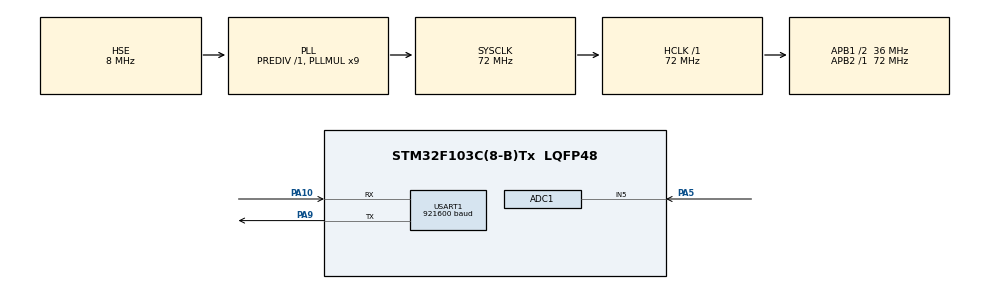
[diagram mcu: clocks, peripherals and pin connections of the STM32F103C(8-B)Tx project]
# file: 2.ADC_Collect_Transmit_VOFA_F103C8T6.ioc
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ADC1.Channel-0\#ChannelRegularConversion=ADC_CHANNEL_5
ADC1.ContinuousConvMode=DISABLE
ADC1.ExternalTrigConv=ADC_EXTERNALTRIGCONV_T3_TRGO
ADC1.NbrOfConversion=1
ADC1.NbrOfConversionFlag=1
ADC1.Rank-0\#ChannelRegularConversion=1
ADC1.SamplingTime-0\#ChannelRegularConversion=ADC_SAMPLETIME_55CYCLES_5
ADC1.master=1
Dma.ADC1.0.Direction=DMA_PERIPH_TO_MEMORY
Dma.ADC1.0.Instance=DMA1_Channel1
Dma.ADC1.0.MemDataAlignment=DMA_MDATAALIGN_HALFWORD
Dma.ADC1.0.MemInc=DMA_MINC_ENABLE
Dma.ADC1.0.Mode=DMA_CIRCULAR
Dma.ADC1.0.PeriphDataAlignment=DMA_PDATAALIGN_HALFWORD
Dma.ADC1.0.PeriphInc=DMA_PINC_DISABLE
Dma.ADC1.0.Priority=DMA_PRIORITY_MEDIUM
Dma.Request0=ADC1
Mcu.Family=STM32F1
Mcu.Name=STM32F103C(8-B)Tx
Mcu.Package=LQFP48
NVIC.DMA1_Channel1_IRQn=true\:0\:0\:false\:false\:true\:false\:true\:true
NVIC.PriorityGroup=NVIC_PRIORITYGROUP_4
PA10.Mode=Asynchronous
PA10.Signal=USART1_RX
PA13.Mode=Serial_Wire
PA13.Signal=SYS_JTMS-SWDIO
PA14.Mode=Serial_Wire
PA14.Signal=SYS_JTCK-SWCLK
PA5.Signal=ADCx_IN5
PA9.Mode=Asynchronous
PA9.Signal=USART1_TX
PD0-OSC_IN.Mode=HSE-External-Oscillator
PD0-OSC_IN.Signal=RCC_OSC_IN
PD1-OSC_OUT.Mode=HSE-External-Oscillator
PD1-OSC_OUT.Signal=RCC_OSC_OUT
ProjectManager.HeapSize=0x200
ProjectManager.StackSize=0x400
ProjectManager.TargetToolchain=CMake
RCC.ADCPresc=RCC_ADCPCLK2_DIV6
RCC.AHBFreq_Value=72000000
RCC.APB1CLKDivider=RCC_HCLK_DIV2
RCC.APB1Freq_Value=36000000
RCC.APB1TimFreq_Value=72000000
RCC.APB2Freq_Value=72000000
RCC.APB2TimFreq_Value=72000000
RCC.HCLKFreq_Value=72000000
RCC.PLLMUL=RCC_PLL_MUL9
RCC.PLLSourceVirtual=RCC_PLLSOURCE_HSE
RCC.SYSCLKFreq_VALUE=72000000
RCC.SYSCLKSource=RCC_SYSCLKSOURCE_PLLCLK
RCC.USBFreq_Value=72000000
SH.ADCx_IN5.0=ADC1_IN5,IN5
TIM3.Period=89
TIM3.Prescaler=79
TIM3.TIM_MasterOutputTrigger=TIM_TRGO_UPDATE
USART1.BaudRate=921600
USART1.VirtualMode=VM_ASYNC
VP_TIM3_VS_ClockSourceINT.Mode=Internal
board=custom

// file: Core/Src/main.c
/* USER CODE BEGIN Header */
/**
  ******************************************************************************
  * @file           : main.c
  * @brief          : Main program body
  ******************************************************************************
  * @attention
  *
  * Copyright (c) 2026 STMicroelectronics.
  * All rights reserved.
  *
  * This software is licensed under terms that can be found in the LICENSE file
  * in the root directory of this software component.
  * If no LICENSE file comes with this software, it is provided AS-IS.
  *
  ******************************************************************************
  */
/* USER CODE END Header */
#include "main.h"
#include "adc.h"
#include "dma.h"
#include "tim.h"
#include "usart.h"
#include "gpio.h"

/* USER CODE BEGIN PV */
extern TIM_HandleTypeDef htim3;             // CubeMX 自动生成在 main.c 全局区
extern uint16_t adc_dma_buf[200];           // 引用 adc.c 的 DMA 缓冲
#define ADC_BUF_SIZE  200
#define HALF_BUF      100

volatile uint8_t half_done = 0;             // 前半满标志
volatile uint8_t full_done = 0;             // 全满标志

float volt_filtered[HALF_BUF];              // 滤波后的浮点电压（供发送）
/* USER CODE END PV */

void SystemClock_Config(void);

/* USER CODE BEGIN 0 */
/* 4 点滑动平均滤波 */
static float smooth_filter(uint16_t *buf, int idx)
{
    int i0 = (idx - 3 + ADC_BUF_SIZE) % ADC_BUF_SIZE;
    int i1 = (idx - 2 + ADC_BUF_SIZE) % ADC_BUF_SIZE;
    int i2 = (idx - 1 + ADC_BUF_SIZE) % ADC_BUF_SIZE;
    float sum = buf[i0] + buf[i1] + buf[i2] + buf[idx];
    return sum * (3.3f / 4095.0f / 4.0f);  // 平均值转为电压
}

/* DMA 前半传输完成回调 */
void HAL_ADC_ConvHalfCpltCallback(ADC_HandleTypeDef* hadc)
{
    if (hadc->Instance == ADC1) {
        for (int i = 0; i < HALF_BUF; i++) {
            volt_filtered[i] = smooth_filter(adc_dma_buf, i);
        }
        half_done = 1;
    }
}

/* DMA 全满传输完成回调 */
void HAL_ADC_ConvCpltCallback(ADC_HandleTypeDef* hadc)
{
    if (hadc->Instance == ADC1) {
        for (int i = HALF_BUF; i < ADC_BUF_SIZE; i++) {
            volt_filtered[i - HALF_BUF] = smooth_filter(adc_dma_buf, i);
        }
        full_done = 1;
    }
}
/* USER CODE END 0 */

int main(void)
{

  /* MCU Configuration--------------------------------------------------------*/

  /* Reset of all peripherals, Initializes the Flash interface and the Systick. */
  HAL_Init();

  /* Configure the system clock */
  SystemClock_Config();

  /* Initialize all configured peripherals */
  MX_GPIO_Init();
  MX_DMA_Init();
  MX_ADC1_Init();
  MX_USART1_UART_Init();
  MX_TIM3_Init();
  /* USER CODE BEGIN 2 */
  /* 手动初始化 PB8 为推挽输出（调试 LED，低电平点亮）*/
  /* LED 初始化 */
  __HAL_RCC_GPIOB_CLK_ENABLE();
  GPIO_InitTypeDef GPIO_InitStruct = {0};
  GPIO_InitStruct.Pin = GPIO_PIN_8;
  GPIO_InitStruct.Mode = GPIO_MODE_OUTPUT_PP;
  GPIO_InitStruct.Pull = GPIO_NOPULL;
  GPIO_InitStruct.Speed = GPIO_SPEED_FREQ_LOW;
  HAL_GPIO_Init(GPIOB, &GPIO_InitStruct);
  /* 启动 TIM3，它将以 10kHz 触发 ADC */
  HAL_TIM_Base_Start(&htim3);

  /* USER CODE END 2 */

  /* Infinite loop */
  while (1)
  {

    /* USER CODE BEGIN 3 */
   /* 处理前半缓冲 */
    if (half_done) {
        half_done = 0;
        for (int i = 0; i < HALF_BUF; i++) {
            HAL_UART_Transmit(&huart1, (uint8_t*)&volt_filtered[i], 4, 10);
            uint8_t tail_magic[4] = {0x00, 0x00, 0x80, 0x7F};
            HAL_UART_Transmit(&huart1, tail_magic, 4, 10);
        }
        HAL_GPIO_TogglePin(GPIOB, GPIO_PIN_8);  // LED 翻转 = 数据已发送
    }

    /* 处理后半缓冲 */
    if (full_done) {
        full_done = 0;
        for (int i = 0; i < HALF_BUF; i++) {
            HAL_UART_Transmit(&huart1, (uint8_t*)&volt_filtered[i], 4, 10);
            uint8_t tail_magic[4] = {0x00, 0x00, 0x80, 0x7F};
            HAL_UART_Transmit(&huart1, tail_magic, 4, 10);
        }
        HAL_GPIO_TogglePin(GPIOB, GPIO_PIN_8);
    }
  }
  /* USER CODE END 3 */
}

void SystemClock_Config(void)
{
  RCC_OscInitTypeDef RCC_OscInitStruct = {0};
  RCC_ClkInitTypeDef RCC_ClkInitStruct = {0};
  RCC_PeriphCLKInitTypeDef PeriphClkInit = {0};

  /** Initializes the RCC Oscillators according to the specified parameters
  * in the RCC_OscInitTypeDef structure.
  */
  RCC_OscInitStruct.OscillatorType = RCC_OSCILLATORTYPE_HSE;
  RCC_OscInitStruct.HSEState = RCC_HSE_ON;
  RCC_OscInitStruct.HSEPredivValue = RCC_HSE_PREDIV_DIV1;
  RCC_OscInitStruct.HSIState = RCC_HSI_ON;
  RCC_OscInitStruct.PLL.PLLState = RCC_PLL_ON;
  RCC_OscInitStruct.PLL.PLLSource = RCC_PLLSOURCE_HSE;
  RCC_OscInitStruct.PLL.PLLMUL = RCC_PLL_MUL9;
  if (HAL_RCC_OscConfig(&RCC_OscInitStruct) != HAL_OK)
  {
    Error_Handler();
  }

  /** Initializes the CPU, AHB and APB buses clocks
  */
  RCC_ClkInitStruct.ClockType = RCC_CLOCKTYPE_HCLK|RCC_CLOCKTYPE_SYSCLK
                              |RCC_CLOCKTYPE_PCLK1|RCC_CLOCKTYPE_PCLK2;
  RCC_ClkInitStruct.SYSCLKSource = RCC_SYSCLKSOURCE_PLLCLK;
  RCC_ClkInitStruct.AHBCLKDivider = RCC_SYSCLK_DIV1;
  RCC_ClkInitStruct.APB1CLKDivider = RCC_HCLK_DIV2;
  RCC_ClkInitStruct.APB2CLKDivider = RCC_HCLK_DIV1;

  if (HAL_RCC_ClockConfig(&RCC_ClkInitStruct, FLASH_LATENCY_2) != HAL_OK)
  {
    Error_Handler();
  }
  PeriphClkInit.PeriphClockSelection = RCC_PERIPHCLK_ADC;
  PeriphClkInit.AdcClockSelection = RCC_ADCPCLK2_DIV6;
  if (HAL_RCCEx_PeriphCLKConfig(&PeriphClkInit) != HAL_OK)
  {
    Error_Handler();
  }
}

void Error_Handler(void)
{
  __disable_irq();
  while (1)
  {
  }
}
